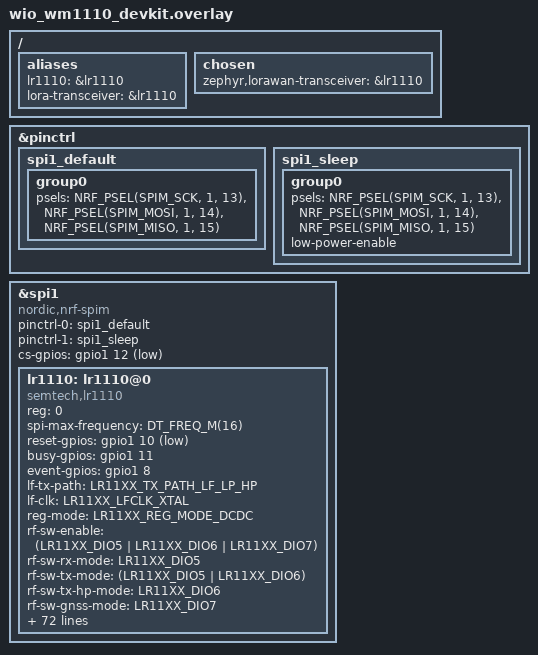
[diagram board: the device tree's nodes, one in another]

#include "user_keys.overlay"

/* LR11xx dt-bindings (macros like LR11XX_TX_PATH_LF_LP_HP, etc.) */
#include <zephyr/dt-bindings/usp/lr11xx.h>

/ {
    aliases {
        lr1110 = &lr1110;
        lora-transceiver = &lr1110;
    };
    chosen {
        zephyr,lorawan-transceiver = &lr1110;
    };

};

&pinctrl {
    spi1_default: spi1_default {
        group0 {
            psels = <NRF_PSEL(SPIM_SCK, 1, 13)>,
                    <NRF_PSEL(SPIM_MOSI, 1, 14)>,
                    <NRF_PSEL(SPIM_MISO, 1, 15)>;
        };
    };

    spi1_sleep: spi1_sleep {
        group0 {
            psels = <NRF_PSEL(SPIM_SCK, 1, 13)>,
                    <NRF_PSEL(SPIM_MOSI, 1, 14)>,
                    <NRF_PSEL(SPIM_MISO, 1, 15)>;
            low-power-enable;
        };
    };
};

&spi1 {
    compatible = "nordic,nrf-spim";
    status = "okay";
    pinctrl-0 = <&spi1_default>;
    pinctrl-1 = <&spi1_sleep>;
    pinctrl-names = "default", "sleep";
    cs-gpios = <&gpio1 12 GPIO_ACTIVE_LOW>;

    lr1110: lr1110@0 {
        compatible = "semtech,lr1110";
        reg = <0>;
        spi-max-frequency = <DT_FREQ_M(16)>;

        reset-gpios = <&gpio1 10 GPIO_ACTIVE_LOW>;
        busy-gpios  = <&gpio1 11 GPIO_ACTIVE_HIGH>;
        event-gpios = <&gpio1 8 GPIO_ACTIVE_HIGH>;

        lf-tx-path = <LR11XX_TX_PATH_LF_LP_HP>;
        lf-clk = <LR11XX_LFCLK_XTAL>;
        reg-mode = <LR11XX_REG_MODE_DCDC>;

        rf-sw-enable     = <(LR11XX_DIO5 | LR11XX_DIO6 | LR11XX_DIO7)>;
        rf-sw-rx-mode    = <LR11XX_DIO5>;
        rf-sw-tx-mode    = <(LR11XX_DIO5 | LR11XX_DIO6)>;
        rf-sw-tx-hp-mode = <LR11XX_DIO6>;
        rf-sw-gnss-mode  = <LR11XX_DIO7>;

        tcxo-voltage = <LR11XX_TCXO_SUPPLY_1_8V>;
        tcxo-wakeup-time = <8>;

        tx-power-cfg-lf-lp =
            /* power, pa_duty_cycle, pa_hp_sel */
            <(-15) 0x00 0x00>,
            <(-14) 0x00 0x00>,
            <(-13) 0x00 0x00>,
            <(-12) 0x00 0x00>,
            <(-11) 0x00 0x00>,
            <(-9) 0x00 0x00>,
            <(-8) 0x00 0x00>,
            <(-7) 0x00 0x00>,
            <(-6) 0x00 0x00>,
            <(-5) 0x00 0x00>,
            <(-4) 0x00 0x00>,
            <(-3) 0x00 0x00>,
            <(-2) 0x00 0x00>,
            <(-1) 0x00 0x00>,
            <( 0) 0x00 0x00>,
            <( 1) 0x00 0x00>,
            <( 2) 0x00 0x00>,
            <( 3) 0x00 0x00>,
            <( 3) 0x01 0x00>,
            <( 4) 0x01 0x00>,
            <( 7) 0x00 0x00>,
            <( 8) 0x00 0x00>,
            <( 9) 0x00 0x00>,
            <( 10) 0x00 0x00>,
            <( 12) 0x00 0x00>,
            <( 13) 0x00 0x00>,
            <( 14) 0x00 0x00>,
            <( 13) 0x01 0x00>,
            <( 13) 0x02 0x00>,
            <( 14) 0x02 0x00>,
            <( 14) 0x03 0x00>,
            <( 14) 0x04 0x00>,
            <( 14) 0x07 0x00>;

        tx-power-cfg-lf-hp =
            /* power, pa_duty_cycle, pa_hp_sel */
            <(  9) 0x00 0x00>,
            <( 10) 0x00 0x00>,
            <( 11) 0x00 0x00>,
            <( 12) 0x00 0x00>,
            <( 13) 0x00 0x00>,
            <( 13) 0x01 0x00>,
            <( 13) 0x02 0x00>,
            <( 17) 0x02 0x00>,
            <( 14) 0x04 0x00>,
            <( 12) 0x00 0x01>,
            <( 13) 0x00 0x01>,
            <( 13) 0x01 0x01>,
            <( 13) 0x02 0x01>,
            <( 15) 0x00 0x02>,
            <( 15) 0x04 0x01>,
            <( 14) 0x02 0x02>,
            <( 14) 0x01 0x03>,
            <( 17) 0x04 0x02>,
            <( 22) 0x00 0x01>,
            <( 22) 0x01 0x01>,
            <( 22) 0x02 0x01>,
            <( 22) 0x03 0x01>,
            <( 22) 0x00 0x03>,
            <( 22) 0x01 0x03>,
            <( 22) 0x04 0x02>,
            <( 22) 0x01 0x04>,
            <( 22) 0x02 0x04>,
            <( 22) 0x01 0x06>,
            <( 22) 0x03 0x05>,
            <( 22) 0x03 0x07>,
            <( 22) 0x04 0x06>,
            <( 22) 0x04 0x07>;

        tx-power-cfg-hf =
            /* power, pa_duty_cycle, pa_hp_sel */
            <(-18) 0x04 0x00>,
            <(-18) 0x04 0x00>,
            <(-17) 0x04 0x00>,
            <(-16) 0x04 0x00>,
            <(-15) 0x04 0x00>,
            <(-14) 0x04 0x00>,
            <(-14) 0x04 0x00>,
            <(-12) 0x04 0x00>,
            <(-10) 0x04 0x00>,
            <( -9) 0x04 0x00>,
            <( -8) 0x04 0x00>,
            <( -7) 0x04 0x00>,
            <( -6) 0x04 0x00>,
            <( -5) 0x04 0x00>,
            <( -4) 0x04 0x00>,
            <( -3) 0x04 0x00>,
            <( -2) 0x03 0x00>,
            <( -1) 0x04 0x00>,
            <(  0) 0x04 0x00>,
            <(  1) 0x00 0x00>,
            <(  2) 0x00 0x00>,
            <(  4) 0x04 0x00>,
            <(  5) 0x04 0x00>,
            <(  6) 0x04 0x00>,
            <(  7) 0x04 0x00>,
            <(  8) 0x04 0x00>,
            <(  9) 0x04 0x00>,
            <( 10) 0x04 0x00>,
            <( 11) 0x04 0x00>,
            <( 12) 0x03 0x00>,
            <( 13) 0x04 0x00>,
            <( 13) 0x00 0x00>;

        rssi-calibration-lf-offset = <0>;
        rssi-calibration-lf-tune = <12 12 14 0 1 3 4 4 3 6 6 6 6 6 6 6 6>;

        rssi-calibration-mf-offset = <0>;
        rssi-calibration-mf-tune = <2 2 2 3 3 4 5 4 4 6 5 5 6 6 6 7 6>;

        rssi-calibration-hf-offset = <2030>;
        rssi-calibration-hf-tune = <6 7 6 4 3 4 14 12 14 12 12 12 12 8 8 9 9>;

        tx-dbm-to-ua-reg-mode-dcdc-lf-lp-vreg = <
            10820 10980 11060 11160 11300 11430 11550 11680 11930 12170 12420 12650 12900
            13280 13600 14120 14600 15090 15780 16490 17250 17850 18720 19640 20560 21400
            22620 23720 25050 26350 27870 28590 37820>;

        tx-dbm-to-ua-reg-mode-ldo-lf-lp-vreg = <
            14950 15280 15530 15770 16020 16290 16550 16760 17280 17770 18250 18750 19250
            19960 20710 21620 22570 23570 24990 26320 27830 29070 30660 32490 34220 35820
            38180 40220 42800 45030 47900 51220 66060>;

        tx-dbm-to-ua-reg-mode-dcdc-lf-hp-vbat = <
            27750 29100 30320 31650 34250 35550 36770 39250 41480 43820 46000 49020 50900
            54200 56330 59050 62210 65270 68600 71920 75500 79500 84130 88470 92200 94340
            96360 98970 102220 106250 111300 113040>;

        tx-dbm-to-ua-reg-mode-ldo-lf-hp-vbat = <
            31310 32700 33970 35270 37900 39140 40380 42860 45150 47400 49600 52600 54460
            57690 59840 62550 65750 68520 72130 75230 78600 82770 87450 91700 95330 97520
            99520 102080 105140 109300 114460 116530>;

        tx-dbm-to-ua-reg-mode-dcdc-hf-vreg = <
            11800 11800 11800 11900 12020 12120 12230 12390 12540 12740 12960 13150 13460
            13770 14070 14460 15030 15440 16030 16980 17590 18270 19060 19900 20740 21610
            22400 23370 24860 26410 26430 27890>;
    };
};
